# STM32U385 register map
File version: 1.0
CPU: CM33 r0p1, little endian, MPU, FPU, 4 interrupt priority bits
Registers are 32-bit, read-write, reset 0x0 unless marked. A register's access mark holds for its fields unless they carry their own. Offsets are from the block's base; [hi:lo] are bit positions; {n}, {i} and the like mark numbered series; 'fields as' and 'values as' point back to an identical list.

## GPDMA1 (part 1 of 2)
Base 0x40020000
Same registers: SEC_GPDMA1 0x50020000
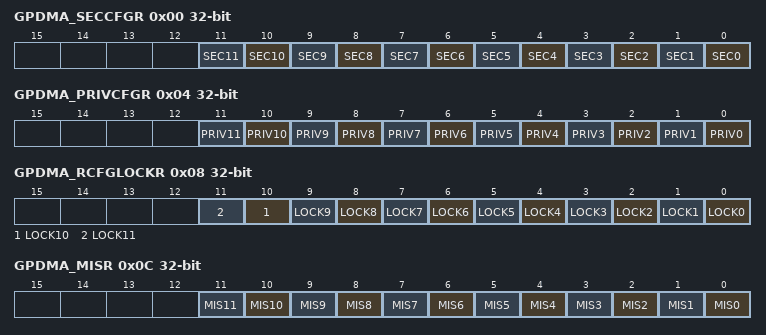
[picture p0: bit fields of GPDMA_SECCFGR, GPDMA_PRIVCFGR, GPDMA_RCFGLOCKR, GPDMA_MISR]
0x00 GPDMA_SECCFGR — GPDMA secure configuration register
  [all] fields
    0=non-secure; 1=secure
  [n] SEC{n} (n=0..11) — None 0: non-secure 1: secure
0x04 GPDMA_PRIVCFGR — GPDMA privileged configuration register
  [all] fields
    0=unprivileged; 1=privileged
  [n] PRIV{n} (n=0..11) — None 0: unprivileged 1: privileged
0x08 GPDMA_RCFGLOCKR — GPDMA configuration lock register
  [n] LOCK{n} (n=0..11) — This bit is cleared after reset and, once set, it cannot be reset until a global GPDMA reset. 0: secure privilege configuration of the channel {n} is writable. 1: secure privilege configuration of the channel {n} is not writable. Note: If TZEN = 0, this register can be written by a privileged access with any secure/non-secure attribute.
    0=secure privilege configuration of the channel {n} is writable; 1=secure privilege configuration of the channel {n} is not writable
0x0C GPDMA_MISR ro — GPDMA non-secure masked interrupt status register
  [n] MIS{n} (n=0..11) — None 0: no interrupt occurred on channel {n} 1: an interrupt occurred on channel {n}
    0=no interrupt occurred on channel {n}; 1=an interrupt occurred on channel {n}
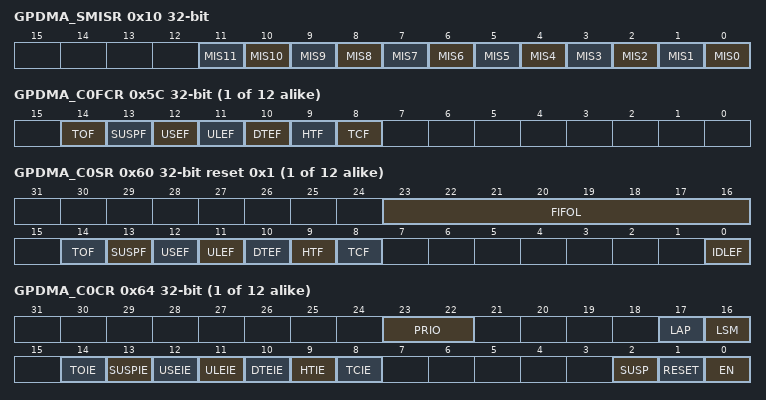
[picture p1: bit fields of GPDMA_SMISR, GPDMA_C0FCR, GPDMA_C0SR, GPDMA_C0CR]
0x10 GPDMA_SMISR ro — GPDMA secure masked interrupt status register
  [n] MIS{n} (n=0..11) — None 0: no interrupt occurred on the secure channel {n} 1: an interrupt occurred on the secure channel {n}
    0=no interrupt occurred on the secure channel {n}; 1=an interrupt occurred on the secure channel {n}
{0x50+0x80*i} GPDMA_C{i}LBAR (i=0..11) — GPDMA channel {i} linked-list base address register
  [31:16] LBA
{0x5C+0x80*i} GPDMA_C{i}FCR wo (i=0..11) — GPDMA channel {i} flag clear register
  [14] TOF — None 0: no effect 1: corresponding TOF flag cleared
    0=no effect; 1=corresponding TOF flag cleared
  [13] SUSPF — None 0: no effect 1: corresponding SUSPF flag cleared
    0=no effect; 1=corresponding SUSPF flag cleared
  [12] USEF — None 0: no effect 1: corresponding USEF flag cleared
    0=no effect; 1=corresponding USEF flag cleared
  [11] ULEF — None 0: no effect 1: corresponding ULEF flag cleared
    0=no effect; 1=corresponding ULEF flag cleared
  [10] DTEF — None 0: no effect 1: corresponding DTEF flag cleared
    0=no effect; 1=corresponding DTEF flag cleared
  [9] HTF — None 0: no effect 1: corresponding HTF flag cleared
    0=no effect; 1=corresponding HTF flag cleared
  [8] TCF — None 0: no effect 1: corresponding TCF flag cleared
    0=no effect; 1=corresponding TCF flag cleared
{0x60+0x80*i} GPDMA_C{i}SR ro reset 0x1 (i=0..11) — GPDMA channel {i} status register
  [23:16] FIFOL — Number of available write beats in the FIFO, in units of the programmed destination data width (see GPDMA_C{i}TR1.DDW_LOG2[1:0], in units of bytes, half-words, or words). Note: After having suspended an active transfer, the user may need to read FIFOL[7:0], additionally to GPDMA_C{i}BR1.BDNT[15:0] and GPDMA_C{i}BR1.BRC[10:0], to know how many data have been transferred to the destination. Before reading, the user may wait for the transfer to be suspended (GPDMA_C{i}SR.SUSPF = 1).
  [14] TOF — None 0: no trigger overrun event 1: a trigger overrun event occurred
    0=no trigger overrun event; 1=a trigger overrun event occurred
  [13] SUSPF — None 0: no completed suspension event 1: a completed suspension event occurred
    0=no completed suspension event; 1=a completed suspension event occurred
  [12] USEF — None 0: no user setting error event 1: a user setting error event occurred
    0=no user setting error event; 1=a user setting error event occurred
  [11] ULEF — None 0: no update link transfer error event 1: a master bus error event occurred while updating a linked-list register from memory
    0=no update link transfer error event; 1=a master bus error event occurred while updating a linked-list register from memory
  [10] DTEF — None 0: no data transfer error event 1: a master bus error event occurred on a data transfer
    0=no data transfer error event; 1=a master bus error event occurred on a data transfer
  [9] HTF — A half transfer event is either a half block transfer or a half 2D/repeated block transfer, depending on the transfer complete event mode (GPDMA_C{i}TR2.TCEM[1:0]). A half block transfer occurs when half of the bytes of the source block size (rounded up integer of GPDMA_C{i}BR1.BNDT[15:0]/2) has been transferred to the destination. A half 2D/repeated block transfer occurs when half of the repeated blocks (rounded up integer of (GPDMA_C{i}BR1.BRC[10:0]+1)/2)) has been transferred to the destination. 0: no half transfer event 1: a half transfer event occurred
    0=no half transfer event; 1=a half transfer event occurred
  [8] TCF — A transfer complete event is either a block transfer complete, a 2D/repeated block transfer complete, or a LLI transfer complete including the upload of the next LLI if any, or the full linked-list completion, depending on the transfer complete event mode (GPDMA_C{i}TR2.TCEM[1:0]). 0: no transfer complete event 1: a transfer complete event occurred
    0=no transfer complete event; 1=a transfer complete event occurred
  [0] IDLEF — This idle flag is deasserted by hardware when the channel is enabled (GPDMA_C{i}CR.EN = 1) with a valid channel configuration (no USEF to be immediately reported). This idle flag is asserted after hard reset or by hardware when the channel is back in idle state (in suspended or disabled state). 0: channel not in idle state 1: channel in idle state
    0=channel not in idle state; 1=channel in idle state
{0x64+0x80*i} GPDMA_C{i}CR access per field (i=0..11) — GPDMA channel {i} control register
  [23:22] PRIO rw — None 00: low priority, low weight 01: low priority, mid weight 10: low priority, high weight 11: high priority Note: This bit must be written when EN = 0. This bit is read-only when EN = 1.
    0=low priority, low weight; 1=low priority, mid weight; 2=low priority, high weight; 3=high priority
  [17] LAP rw — This bit is used to allocate the master port for the update of the GPDMA linked-list registers from the memory. 0: port 0 (AHB) allocated 1: port 1 (AHB) allocated Note: This bit must be written when EN = 0. This bit is read-only when EN = 1.
    0=port 0 (AHB) allocated; 1=port 1 (AHB) allocated
  [16] LSM rw — First the (possible 1D/repeated) block transfer is executed as defined by the current internal register file until GPDMA_C{i}BR1.BNDT[15:0] = 0 and GPDMA_C{i}BR1.BRC[10:0] = 0. Secondly the next linked-list data structure is conditionally uploaded from memory as defined by GPDMA_C{i}LLR. Then channel execution is completed. 0: channel executed for the full linked-list and completed at the end of the last LLI (GPDMA_C{i}LLR = 0). The 16 low-significant bits of the link address are null (LA[15:0] = 0) and all the update bits are null (UT1 = UB1 = UT2 = USA = UDA = ULL = 0 and UT3 = UB2 = 0). Then GPDMA_C{i}BR1.BNDT[15:0] = 0 and GPDMA_C{i}BR1.BRC[10:0] = 0. 1: channel executed once for the current LLI Note: This bit must be written when EN = 0. This bit is read-only when EN = 1.
    0=channel executed for the full linked-list and completed at the end of the last LLI (GPDMA_C{i}LLR = 0). The 16 low-significant bits of the link address are null (LA[15:0] = 0) and all the update bits are null (UT1 = UB1 = UT2 = USA = UDA = ULL = 0 and UT3 = UB2 = 0). Then GPDMA_C{i}BR1.BNDT[15:0] = 0 and GPDMA_C{i}BR1.BRC[10:0] = 0.; 1=channel executed once for the current LLI
  [14] TOIE rw — None 0: interrupt disabled 1: interrupt enabled
    0=interrupt disabled; 1=interrupt enabled
  [13] SUSPIE rw — None 0: interrupt disabled 1: interrupt enabled
    0=interrupt disabled; 1=interrupt enabled
  [12] USEIE rw — None 0: interrupt disabled 1: interrupt enabled
    0=interrupt disabled; 1=interrupt enabled
  [11] ULEIE rw — None 0: interrupt disabled 1: interrupt enabled
    0=interrupt disabled; 1=interrupt enabled
  [10] DTEIE rw — None 0: interrupt disabled 1: interrupt enabled
    0=interrupt disabled; 1=interrupt enabled
  [9] HTIE rw — None 0: interrupt disabled 1: interrupt enabled
    0=interrupt disabled; 1=interrupt enabled
  [8] TCIE rw — None 0: interrupt disabled 1: interrupt enabled
    0=interrupt disabled; 1=interrupt enabled
  [2] SUSP rw — Writing 1 into the field RESET (bit 1) causes the hardware to de-assert this bit, whatever is written into this bit 2. Else: Software must write 1 in order to suspend an active channel (channel with an ongoing GPDMA transfer over its master ports). The software must write 0 in order to resume a suspended channel, following the programming sequence detailed in less than xe5 [GPDMA_channel_suspend_and_resume/ID00-1456]/>. 0: write: resume channel, read: channel not suspended 1: write: suspend channel, read: channel suspended.
    0=write: resume channel, read: channel not suspended; 1=write: suspend channel, read: channel suspended
  [1] RESET wo — This bit is write only. Writing 0 has no impact. Writing 1 implies the reset of the following: the FIFO, the channel internal state, SUSP and EN bits (whatever is written receptively in bit 2 and bit 0). The reset is effective when the channel is in steady state, meaning one of the following: - active channel in suspended state (GPDMA_C{i}SR.SUSPF = 1 and GPDMA_C{i}SR.IDLEF=GPDMA_C{i}CR.EN = 1) - channel in disabled state (GPDMA_C{i}SR.IDLEF = 1 and GPDMA_C{i}CR.EN = 0). After writing a RESET, to continue using this channel, the user must explicitly reconfigure the channel including the hardware-modified configuration registers (GPDMA_C{i}BR1, GPDMA_CxSAR and GPDMA_CxDAR) before enabling again the channel (see the programming sequence in less than xe6 [GPDMA_abort_restart/ID00-1465]/>). 0: no channel reset 1: channel reset
    0=no channel reset; 1=channel reset
  [0] EN rw — Writing 1 into the field RESET (bit 1) causes the hardware to de-assert this bit, whatever is written into this bit 0. Else: this bit is deasserted by hardware when there is a transfer error (master bus error or user setting error) or when there is a channel transfer complete (channel ready to be configured, for example if LSM = 1 at the end of a single execution of the LLI). Else, this bit can be asserted by software. Writing 0 into this EN bit is ignored. 0: write: ignored, read: channel disabled 1: write: enable channel, read: channel enabled
    0=write: ignored, read: channel disabled; 1=write: enable channel, read: channel enabled
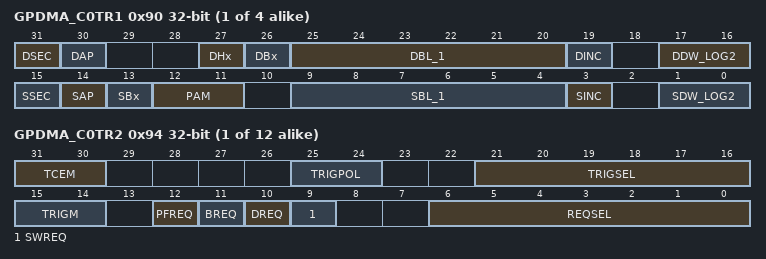
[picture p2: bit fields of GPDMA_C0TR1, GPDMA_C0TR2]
{0x90+0x80*i} GPDMA_C{i}TR1 (i=0..3) — GPDMA channel {i} transfer register 1
  [31] DSEC — If GPDMA_SECCFGR.SEC{i} = 1 and the access is secure: This is a secure register bit. This bit can only be read by a secure software. This bit must be written by a secure software when GPDMA_SECCFGR.SEC{i} = 1. A secure write is ignored when GPDMA_SECCFGR.SEC{i} = 0. When GPDMA_SECCFGR.SEC{i} is deasserted, this DSEC bit is also deasserted by hardware (on a secure reconfiguration of the channel as non-secure), and the GPDMA transfer to the destination is non-secure. 0: GPDMA transfer non-secure 1: GPDMA transfer secure
    0=GPDMA transfer non-secure; 1=GPDMA transfer secure
  [30] DAP — This bit is used to allocate the master port for the destination transfer 0: port 0 (AHB) allocated 1: port 1 (AHB) allocated Note: This bit must be written when EN = 0. This bit is read-only when EN = 1.
    0=port 0 (AHB) allocated; 1=port 1 (AHB) allocated
  [27] DHx — If the destination data size is shorter than a word, this bit is ignored. If the destination data size is a word: 0: no halfword-based exchanged within word 1: the two consecutive (post PAM) half-words are exchanged in each destination word.
    0=no halfword-based exchanged within word; 1=the two consecutive (post PAM) half-words are exchanged in each destination word
  [26] DBx — If the destination data size is a byte, this bit is ignored. If the destination data size is not a byte: 0: no byte-based exchange within half-word 1: the two consecutive (post PAM) bytes are exchanged in each destination half-word.
    0=no byte-based exchange within half-word; 1=the two consecutive (post PAM) bytes are exchanged in each destination half-word
  [25:20] DBL_1 — The burst length unit is one data named beat within a burst. If DBL_1[5:0] = 0, the burst can be named as single. Each data/beat has a width defined by the destination data width DDW_LOG2[1:0]. Note: If a burst transfer crossed a 1-Kbyte address boundary on a AHB transfer, the GPDMA modifies and shortens the programmed burst into singles or bursts of lower length, to be compliant with the AHB protocol. +: If a burst transfer is of length greater than the FIFO size of the channel {i}, the GPDMA modifies and shortens the programmed burst into singles or bursts of lower length, to be compliant with the FIFO size. Transfer performance is lower, with GPDMA re-arbitration between effective and lower singles/bursts, but the data integrity is guaranteed.
  [19] DINC — The destination address, pointed by GPDMA_CxDAR, is kept constant after a burst beat/single transfer, or is incremented by the offset value corresponding to a contiguous data after a burst beat/single transfer. 0: fixed burst 1: contiguously incremented burst
    0=fixed burst; 1=contiguously incremented burst
  [17:16] DDW_LOG2 — None 00: byte 01: half-word (2 bytes) 10: word (4 bytes) 11: user setting error reported and no transfer issued Note: Setting a 8-byte data width causes a user setting error to be reported and none transfer is issued. +: A destination burst transfer must have an aligned address with its data width (start address GPDMA_CxDAR[2:0] and address offset GPDMA_CxTR3.DAO[2:0], versus DDW_LOG2[1:0]). Otherwise a user setting error is reported and no transfer is issued.
    0=byte; 1=half-word (2 bytes); 2=word (4 bytes); 3=user setting error reported and no transfer issued
  [15] SSEC — If GPDMA_SECCFGR.SEC{i} = 1 and the access is secure: This is a secure register bit. This bit can only be read by a secure software. This bit must be written by a secure software when GPDMA_SECCFGR.SEC{i} = 1. A secure write is ignored when GPDMA_SECCFGR.SEC{i} = 0. When GPDMA_SECCFGR.SEC{i} is deasserted, this SSEC bit is also deasserted by hardware (on a secure reconfiguration of the channel as non-secure), and the GPDMA transfer from the source is non-secure. 0: GPDMA transfer non-secure 1: GPDMA transfer secure
    0=GPDMA transfer non-secure; 1=GPDMA transfer secure
  [14] SAP — This bit is used to allocate the master port for the source transfer 0: port 0 (AHB) allocated 1: port 1 (AHB) allocated Note: This bit must be written when EN = 0. This bit is read-only when EN = 1.
    0=port 0 (AHB) allocated; 1=port 1 (AHB) allocated
  [13] SBx — If the source data width is shorter than a word, this bit is ignored. If the source data width is a word: 0: no byte-based exchange within the unaligned half-word of each source word 1: the two consecutive bytes within the unaligned half-word of each source word are exchanged.
    0=no byte-based exchange within the unaligned half-word of each source word; 1=the two consecutive bytes within the unaligned half-word of each source word are exchanged
  [12:11] PAM — If DDW_LOG2[1:0] = SDW_LOG2[1:0]: if the data width of a burst destination transfer is equal to the data width of a burst source transfer, these bits are ignored.
    0=B_0x0_COND1 (COND1 is [PAM_1] source data is transferred as right aligned, padded with 0s up to the destination data width); 1=B_0x1_COND1 (COND1 is [PAM_1] source data is transferred as right aligned, sign extended up to the destination data width); 2=B_0x2_COND1 (COND1 is [PAM_1] successive source data are FIFO queued and packed at the destination data width, in a left (LSB) to right (MSB) order (named little endian), before a destination transfer); 3=B_0x3_COND1 (COND1 is [PAM_1] successive source data are FIFO queued and packed at the destination data width, in a left (LSB) to right (MSB) order (named little endian), before a destination transfer)
  [9:4] SBL_1 — The burst length unit is one data named beat within a burst. If SBL_1[5:0] = 0, the burst can be named as single. Each data/beat has a width defined by the destination data width SDW_LOG2[1:0]. Note: If a burst transfer crossed a 1-Kbyte address boundary on a AHB transfer, the GPDMA modifies and shortens the programmed burst into singles or bursts of lower length, to be compliant with the AHB protocol. +: If a burst transfer is of length greater than the FIFO size of the channel {i}, the GPDMA modifies and shortens the programmed burst into singles or bursts of lower length, to be compliant with the FIFO size. Transfer performance is lower, with GPDMA re-arbitration between effective and lower singles/bursts, but the data integrity is guaranteed.
  [3] SINC — The source address, pointed by GPDMA_CxSAR, is kept constant after a burst beat/single transfer or is incremented by the offset value corresponding to a contiguous data after a burst beat/single transfer. 0: fixed burst 1: contiguously incremented burst
    0=fixed burst; 1=contiguously incremented burst
  [1:0] SDW_LOG2 — None 00: byte 01: half-word (2 bytes) 10: word (4 bytes) 11: user setting error reported and no transfer issued Note: Setting a 8-byte data width causes a user setting error to be reported and no transfer is issued. +: A source block size must be a multiple of the source data width (GPDMA_C{i}BR1.BNDT[2:0] versus SDW_LOG2[1:0]). Otherwise, a user setting error is reported and no transfer is issued. +: A source burst transfer must have an aligned address with its data width (start address GPDMA_CxSAR[2:0] versus SDW_LOG2[1:0]). Otherwise, a user setting error is reported and none transfer is issued.
    values as DDW_LOG2
{0x94+0x80*i} GPDMA_C{i}TR2 (i=0..11) — GPDMA channel {i} transfer register 2
  [31:30] TCEM — These bits define the transfer granularity for the transfer complete and half transfer complete events generation. 00: at block level (when GPDMA_C{i}BR1.BNDT[15:0] = 0): the complete (and the half) transfer event is generated at the (respectively half of the) end of a block. 01: channel {i} (0 to ), same as 00, channel {i} , at 2D/repeated block level (when GPDMA_C{i}BR1.BRC[10:0] = 0 and GPDMA_C{i}BR1.BNDT[15:0] = 0). The complete (and the half) transfer event is generated at the end (respectively half of the end) of the 2D/repeated block. 10: at LLI level: the complete transfer event is generated at the end of the LLI transfer, including the update of the LLI if any. The half transfer event is generated at the half of the LLI data transfer. The LLI data transfer is a block transfer or a 2D/repeated block transfer for channel {i} , if any data transfer. 11: at channel level: the complete transfer event is generated at the end of the last LLI transfer. The half transfer event is generated at the half of the data transfer of the last LLI. The last LLI updates the link address GPDMA_C{i}LLR.LA[15:2] to zero and clears all the GPDMA_C{i}LLR update bits (UT1, UT2, UB1, USA, UDA and ULL, plus UT3 and UB2). If the channel transfer is continuous/infinite, no event is generated. Note: If the initial LLI0 data transfer is null/void (directly programmed by the internal register file with GPDMA_C{i}BR1.BNDT[15:0] = 0), then neither the complete transfer event nor the half transfer event is generated. +: If the initial LLI0 data transfer is null/void (directly programmed by the internal register file with GPDMA_C{i}BR1.BNDT[15:0] = 0), then neither the complete transfer event nor the half transfer event is generated. +: If the initial LLI0 data transfer is null/void (directly programmed by the internal register file with GPDMA_C{i}BR1.BNDT[15:0] = 0), then the half transfer event is not generated, and the transfer complete event is generated when is completed the loading of the LLI1.
    0=at block level (when GPDMA_C{i}BR1.BNDT[15:0] = 0): the complete (and the half) transfer event is generated at the (respectively half of the) end of a block; 1=channel {i} (0 to ), same as 00, channel {i} , at 2D/repeated block level (when GPDMA_C{i}BR1.BRC[10:0] = 0 and GPDMA_C{i}BR1.BNDT[15:0] = 0). The complete (and the half) transfer event is generated at the end (respectively half of the end) of the 2D/repeated block.; 2=at LLI level: the complete transfer event is generated at the end of the LLI transfer, including the update of the LLI if any. The half transfer event is generated at the half of the LLI data transfer. The LLI data transfer is a block transfer or a 2D/repeated block transfer for channel {i} , if any data transfer.; 3=at channel level: the complete transfer event is generated at the end of the last LLI transfer. The half transfer event is generated at the half of the data transfer of the last LLI. The last LLI updates the link address GPDMA_C{i}LLR.LA[15:2] to zero and clears all the GPDMA_C{i}LLR update bits (UT1, UT2, UB1, USA, UDA and ULL, plus UT3 and UB2). If the channel transfer is continuous/infinite, no event is generated.
  [25:24] TRIGPOL — These bits define the polarity of the selected trigger event input defined by TRIGSEL[5:0]. 00: no trigger (masked trigger event) 01: trigger on the rising edge 10: trigger on the falling edge 11: same as 00
    0=no trigger (masked trigger event); 1=trigger on the rising edge; 2=trigger on the falling edge; 3=same as 00
  [21:16] TRIGSEL — These bits select the trigger event input of the GPDMA transfer (as per less than xe3 [GPDMA_triggers]/>), with anactive trigger event if TRIGPOL[1:0] is not equal to 00.
  [15:14] TRIGM — These bits define the transfer granularity for its conditioning by the trigger. If the channel {i} is enabled (GPDMA_C{i}CR.EN asserted) with TRIGPOL[1:0] = 00 or 11, these TRIGM[1:0] bits are ignored. Else, a GPDMA transfer is conditioned by at least one trigger hit: 00: at block level: the first burst read of each block transfer is conditioned by one hit trigger (channel {i} = 12 to 15, for each block if a 2D/repeated block is configured with GPDMA_C{i}BR1.BRC[10:0] is not equal to 0). 10: at link level: a LLI link transfer is conditioned by one hit trigger. The LLI data transfer (if any) is not conditioned. 11: at programmed burst level: If SWREQ = 1, each programmed burst read is conditioned by one hit trigger. If SWREQ = 0, each programmed burst that is requested by the selected peripheral, is conditioned by one hit trigger. - If the peripheral is programmed as a source (DREQ = 0) of the LLI data transfer, each programmed burst read is conditioned. - If the peripheral is programmed as a destination (DREQ = 1) of the LLI data transfer, each programmed burst write is conditioned. The first memory burst read of a (possibly 2D/repeated) block, also named as the first ready FIFO-based source burst, is gated by the occurrence of both the hardware request and the first trigger hit.01: channel {i} = 0 to , same as 00; channel {i} , at 2D/repeated block level. The first burst read of a 2D/repeated block transfer is conditioned by one hit trigger. The GPDMA monitoring of a trigger for channel {i} is started when the channel is enabled/loaded with a new active trigger configuration: rising or falling edge on a selected trigger (TRIGPOL[1:0] = 01 or respectively TRIGPOL[1:0]=10). The monitoring of this trigger is kept active during the triggered and uncompleted (data or link) transfer; and if a new trigger is detected then, this hit is internally memorized to grant the next transfer, as long as the defined rising or falling edge is not modified, and the TRIGSEL[5:0] is not modified, and the channel is enabled. Transferring a next LLIn+1 that updates the GPDMA_C{i}TR2 with a new value for any of TRIGSEL[5:0] or TRIGPOL[1:0], resets the monitoring, trashing the memorized hit of the formerly defined LLIn trigger. After a first new trigger hitn+1 is memorized, if another second trigger hitn+2 is detected and if the hitn triggered transfer is still not completed, hitn+2 is lost and not memorized.memorized. A trigger overrun flag is reported (GPDMA_C{i}SR.TOF=1), and an interrupt is generated if enabled (GPDMA_C{i}CR.TOIE = 1). The channel is not automatically disabled by hardware due to a trigger overrun. Note: When the source block size is not a multiple of the source burst size and is a multiple of the source data width, then the last programmed source burst is not completed and is internally shorten to match the block size. In this case, if TRIGM[1:0] = 11 and (SWREQ = 1 or (SWREQ = 0 and DREQ = 0)), the shortened burst transfer (by singles or/and by bursts of lower length) is conditioned once by the trigger. +: When the programmed destination burst is internally shortened by singles or/and by bursts of lower length (versus FIFO size, versus block size, 1-Kbyte boundary address crossing): if the trigger is conditioning the programmed destination burst (if TRIGM[1:0] = 11 and SWREQ = 0 and DREQ = 1), this shortened destination burst transfer is conditioned once by the trigger.
  [12] PFREQ — Caution: If a given channel {i} is not implemented with this feature, this bit is reserved and PFREQ is not present (see less than xe1 [GPDMA_channels]/> for the list of the implemented channels with this feature).
    0=the selected hardware request is driven by a peripheral with a hardware request/acknowledge protocol in GPDMA control mode. The GPDMA is programmed with GPDMA_C{i}TR1.BNDT[15:0] and this is internally used by the hardware for the block transfer completion.; 1=the selected hardware request is driven by a peripheral with a hardware request/acknowledge protocol in peripheral control mode. The GPDMA block transfer can be early completed by the peripheral itself (see less than xe2 [GPDMA_channels_peripheral]/> for more details).
  [11] BREQ — If the channel {i} is activated (GPDMA_C{i}CR.EN asserted) with SWREQ = 1 (software request for a memory-to-memory transfer), this bit is ignored. Else: 0: the selected hardware request is driven by a peripheral with a hardware request/acknowledge protocol at a burst level. 1: the selected hardware request is driven by a peripheral with a hardware request/acknowledge protocol at a block level (see less than xe4 [GPDMA_requests]/>).
    0=the selected hardware request is driven by a peripheral with a hardware request/acknowledge protocol at a burst level; 1=the selected hardware request is driven by a peripheral with a hardware request/acknowledge protocol at a block level (see less than xe4 [GPDMA_requests]/>)
  [10] DREQ — This bit is ignored if channel {i} is activated (GPDMA_C{i}CR.EN asserted) with SWREQ = 1 (software request for a memory-to-memory transfer). Else: 0: selected hardware request driven by a source peripheral (request signal taken into account by the GPDMA transfer scheduler over the source/read port) 1: selected hardware request driven by a destination peripheral (request signal taken into account by the GPDMA transfer scheduler over the destination/write port) Note: If the channel {i} is activated (GPDMA_C{i}CR.EN is asserted) with SWREQ = 0 and PFREQ = 1 (peripheral hardware request with peripheral flow-control mode), any software assertion to this DREQ bit is ignored: in peripheral flow-control mode, only a peripheral-to-memory transfer is supported.
    0=selected hardware request driven by a source peripheral (request signal taken into account by the GPDMA transfer scheduler over the source/read port); 1=selected hardware request driven by a destination peripheral (request signal taken into account by the GPDMA transfer scheduler over the destination/write port)
  [9] SWREQ — This bit is internally taken into account when GPDMA_C{i}CR.EN is asserted. 0: no software request. The selected hardware request REQSEL[6:0] is taken into account. 1: software request for a memory-to-memory transfer. The default selected hardware request as per REQSEL[6:0] is ignored.
    0=no software request. The selected hardware request REQSEL[6:0] is taken into account.; 1=software request for a memory-to-memory transfer. The default selected hardware request as per REQSEL[6:0] is ignored.
  [6:0] REQSEL — These bits are ignored if channel {i} is activated (GPDMA_C{i}CR.EN asserted) with SWREQ=1 (software request for a memory-to-memory transfer). Else, the selected hardware request is internally taken into account as per less than xe4 [GPDMA_requests]/>. The user must not assign a same input hardware request (same REQSEL[6:0] value) to different active GPDMA channels (GPDMA_C{i}CR.EN = 1 and GPDMA_C{i}TR2.SWREQ = 0 for these channels). GPDMA is not intended to hardware support the case of simultaneous enabled channels incorrectly configured with a same hardware peripheral request signal, and there is no user setting error reporting.
{0x98+0x80*i} GPDMA_C{i}BR1 (i=0..9) — GPDMA channel {i} block register 1
  [15:0] BNDT — Block size transferred from the source. When the channel is enabled, this field becomes read-only and is decremented, indicating the remaining number of data items in the current source block to be transferred. BNDT[15:0] is programmed in number of bytes, maximum source block size is 64 Kbytes -1. Once the last data transfer is completed (BNDT[15:0] = 0): - if GPDMA_C{i}LLR.UB1 = 1, this field is updated by the LLI in the memory. - if GPDMA_C{i}LLR.UB1 = 0 and if there is at least one not null Uxx update bit, this field is internally restored to the programmed value. - if all GPDMA_C{i}LLR.Uxx = 0 and if GPDMA_C{i}LLR.LA[15:0] is not equal to 0, this field is internally restored to the programmed value (infinite/continuous last LLI). - if GPDMA_C{i}LLR = 0, this field is kept as zero following the last LLI data transfer. Note: A non-null source block size must be a multiple of the source data width (BNDT[2:0] versus GPDMA_C{i}TR1.SDW_LOG2[1:0]). Else a user setting error is reported and no transfer is issued. +: When configured in packing mode (GPDMA_C{i}TR1.PAM[1] = 1 and destination data width different from source data width), a non-null source block size must be a multiple of the destination data width (BNDT[2:0] versus GPDMA_C{i}TR1.DDW_LOG2[1:0]). Else a user setting error is reported and no transfer is issued.
{0x9C+0x80*i} GPDMA_C{i}SAR (i=0..11) — GPDMA channel {i} source address register
  [31:0] SA — This field is the pointer to the address from which the next data is read. During the channel activity, depending on the source addressing mode (GPDMA_C{i}TR1.SINC), this field is kept fixed or incremented by the data width (GPDMA_C{i}TR1.SDW_LOG2[1:0]) after each burst source data, reflecting the next address from which data is read. During the channel activity, this address is updated after each completed source burst, consequently to: - the programmed source burst; either in fixed addressing mode or in contiguous-data incremented mode. If contiguously incremented (GPDMA_C{i}TR1.SINC = 1), then the additional address offset value is the programmed burst size, as defined by GPDMA_C{i}TR1.SBL_1[5:0] and GPDMA_C{i}TR1.SDW_LOG2[21:0] - the additional source incremented/decremented offset value as programmed by GPDMA_C{i}BR1.SDEC and GPDMA_CxTR3.SAO[12:0]. - once/if completed source block transfer, for a channel {i} with 2D addressing capability (x = 12 to 15). additional block repeat source incremented/decremented offset value as programmed by GPDMA_C{i}BR1.BRSDEC and GPDMA_CxBR2.BRSAO[15:0] In linked-list mode, after a LLI data transfer is completed, this register is automatically updated by GPDMA from the memory, provided the LLI is set with GPDMA_C{i}LLR.USA = 1. Note: A source address must be aligned with the programmed data width of a source burst (SA[2:0] versus GPDMA_C{i}TR1.SDW_LOG2[1:0]). Else, a user setting error is reported and no transfer is issued. +: When the source block size is not a multiple of the source burst size and is a multiple of the source data width, the last programmed source burst is not completed and is internally shorten to match the block size. In this case, the additional GPDMA_CxTR3.SAO[12:0] is not applied.
